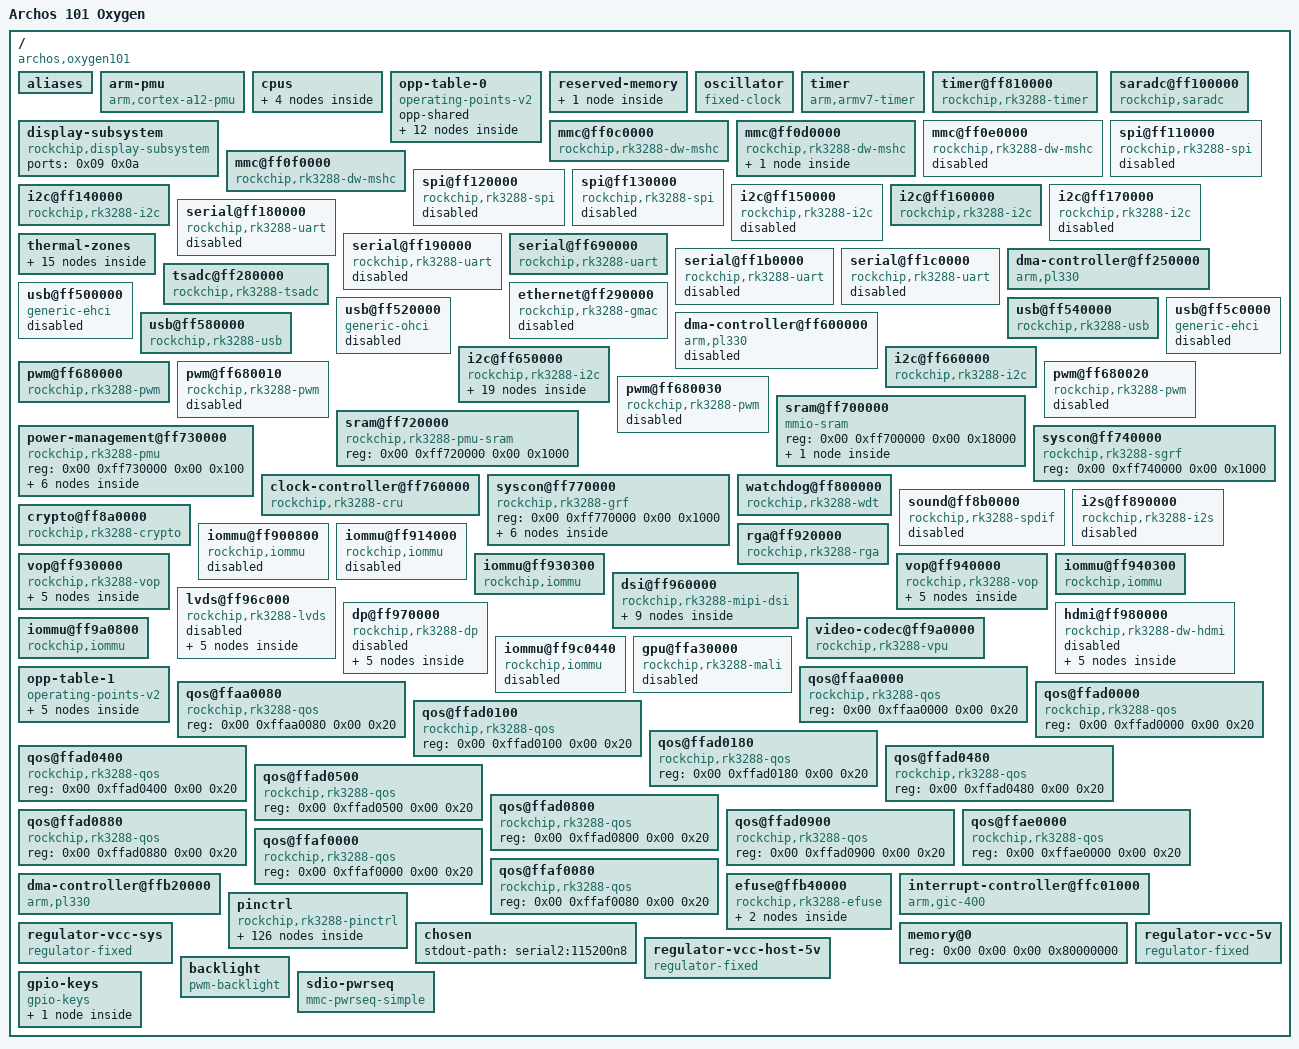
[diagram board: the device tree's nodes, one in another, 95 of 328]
/dts-v1/;

/ {
	#address-cells = <0x02>;
	#size-cells = <0x02>;
	compatible = "archos,oxygen101", "rockchip,rk3288";
	interrupt-parent = <0x01>;
	model = "Archos 101 Oxygen";

	aliases {
		ethernet0 = "/ethernet@ff290000";
		gpio0 = "/pinctrl/gpio@ff750000";
		gpio1 = "/pinctrl/gpio@ff780000";
		gpio2 = "/pinctrl/gpio@ff790000";
		gpio3 = "/pinctrl/gpio@ff7a0000";
		gpio4 = "/pinctrl/gpio@ff7b0000";
		gpio5 = "/pinctrl/gpio@ff7c0000";
		gpio6 = "/pinctrl/gpio@ff7d0000";
		gpio7 = "/pinctrl/gpio@ff7e0000";
		gpio8 = "/pinctrl/gpio@ff7f0000";
		i2c0 = "/i2c@ff650000";
		i2c1 = "/i2c@ff140000";
		i2c2 = "/i2c@ff660000";
		i2c3 = "/i2c@ff150000";
		i2c4 = "/i2c@ff160000";
		i2c5 = "/i2c@ff170000";
		mshc0 = "/mmc@ff0f0000";
		mshc1 = "/mmc@ff0c0000";
		mshc2 = "/mmc@ff0d0000";
		mshc3 = "/mmc@ff0e0000";
		serial0 = "/serial@ff180000";
		serial1 = "/serial@ff190000";
		serial2 = "/serial@ff690000";
		serial3 = "/serial@ff1b0000";
		serial4 = "/serial@ff1c0000";
		spi0 = "/spi@ff110000";
		spi1 = "/spi@ff120000";
		spi2 = "/spi@ff130000";
		mmc0 = "/mmc@ff0f0000";
		mmc1 = "/mmc@ff0c0000";
		mmc2 = "/mmc@ff0d0000";
	};

	arm-pmu {
		compatible = "arm,cortex-a12-pmu";
		interrupts = <0x00 0x97 0x04 0x00 0x98 0x04 0x00 0x99 0x04 0x00 0x9a 0x04>;
		interrupt-affinity = <0x02 0x03 0x04 0x05>;
	};

	cpus {
		#address-cells = <0x01>;
		#size-cells = <0x00>;
		enable-method = "rockchip,rk3066-smp";
		rockchip,pmu = <0x06>;

		cpu@500 {
			device_type = "cpu";
			compatible = "arm,cortex-a12";
			reg = <0x500>;
			resets = <0x07 0x00>;
			#cooling-cells = <0x02>;
			clock-latency = <0x9c40>;
			clocks = <0x07 0x06>;
			dynamic-power-coefficient = <0x172>;
			phandle = <0x02>;
		};

		cpu@501 {
			device_type = "cpu";
			compatible = "arm,cortex-a12";
			reg = <0x501>;
			resets = <0x07 0x01>;
			#cooling-cells = <0x02>;
			clock-latency = <0x9c40>;
			clocks = <0x07 0x06>;
			dynamic-power-coefficient = <0x172>;
			phandle = <0x03>;
		};

		cpu@502 {
			device_type = "cpu";
			compatible = "arm,cortex-a12";
			reg = <0x502>;
			resets = <0x07 0x02>;
			#cooling-cells = <0x02>;
			clock-latency = <0x9c40>;
			clocks = <0x07 0x06>;
			dynamic-power-coefficient = <0x172>;
			phandle = <0x04>;
		};

		cpu@503 {
			device_type = "cpu";
			compatible = "arm,cortex-a12";
			reg = <0x503>;
			resets = <0x07 0x03>;
			#cooling-cells = <0x02>;
			clock-latency = <0x9c40>;
			clocks = <0x07 0x06>;
			dynamic-power-coefficient = <0x172>;
			phandle = <0x05>;
		};
	};

	opp-table-0 {
		compatible = "operating-points-v2";
		opp-shared;

		opp-126000000 {
			opp-hz = <0x00 0x7829b80>;
			opp-microvolt = <0xdbba0>;
		};

		opp-216000000 {
			opp-hz = <0x00 0xcdfe600>;
			opp-microvolt = <0xdbba0>;
		};

		opp-312000000 {
			opp-hz = <0x00 0x1298be00>;
			opp-microvolt = <0xdbba0>;
		};

		opp-408000000 {
			opp-hz = <0x00 0x18519600>;
			opp-microvolt = <0xdbba0>;
		};

		opp-600000000 {
			opp-hz = <0x00 0x23c34600>;
			opp-microvolt = <0xdbba0>;
		};

		opp-696000000 {
			opp-hz = <0x00 0x297c1e00>;
			opp-microvolt = <0xe7ef0>;
		};

		opp-816000000 {
			opp-hz = <0x00 0x30a32c00>;
			opp-microvolt = <0xf4240>;
		};

		opp-1008000000 {
			opp-hz = <0x00 0x3c14dc00>;
			opp-microvolt = <0x100590>;
		};

		opp-1200000000 {
			opp-hz = <0x00 0x47868c00>;
			opp-microvolt = <0x10c8e0>;
		};

		opp-1416000000 {
			opp-hz = <0x00 0x54667200>;
			opp-microvolt = <0x124f80>;
		};

		opp-1512000000 {
			opp-hz = <0x00 0x5a1f4a00>;
			opp-microvolt = <0x13d620>;
		};

		opp-1608000000 {
			opp-hz = <0x00 0x5fd82200>;
			opp-microvolt = <0x149970>;
		};
	};

	reserved-memory {
		#address-cells = <0x02>;
		#size-cells = <0x02>;
		ranges;

		dma-unusable@fe000000 {
			reg = <0x00 0xfe000000 0x00 0x1000000>;
		};
	};

	oscillator {
		compatible = "fixed-clock";
		clock-frequency = <0x16e3600>;
		clock-output-names = "xin24m";
		#clock-cells = <0x00>;
		phandle = <0x08>;
	};

	timer {
		compatible = "arm,armv7-timer";
		arm,cpu-registers-not-fw-configured;
		interrupts = <0x01 0x0d 0xf04 0x01 0x0e 0xf04 0x01 0x0b 0xf04 0x01 0x0a 0xf04>;
		clock-frequency = <0x16e3600>;
		arm,no-tick-in-suspend;
	};

	timer@ff810000 {
		compatible = "rockchip,rk3288-timer";
		reg = <0x00 0xff810000 0x00 0x20>;
		interrupts = <0x00 0x48 0x04>;
		clocks = <0x07 0x161 0x08>;
		clock-names = "pclk", "timer";
	};

	display-subsystem {
		compatible = "rockchip,display-subsystem";
		ports = <0x09 0x0a>;
	};

	mmc@ff0c0000 {
		compatible = "rockchip,rk3288-dw-mshc";
		max-frequency = <0x8f0d180>;
		clocks = <0x07 0x1c8 0x07 0x44 0x07 0x72 0x07 0x76>;
		clock-names = "biu", "ciu", "ciu-drive", "ciu-sample";
		fifo-depth = <0x100>;
		interrupts = <0x00 0x20 0x04>;
		reg = <0x00 0xff0c0000 0x00 0x4000>;
		resets = <0x07 0x80>;
		reset-names = "reset";
		status = "okay";
		bus-width = <0x04>;
		cap-sd-highspeed;
		broken-cd;
		card-detect-delay = <0xc8>;
		disable-wp;
		pinctrl-names = "default";
		pinctrl-0 = <0x0b 0x0c 0x0d>;
		vmmc-supply = <0x0e>;
	};

	mmc@ff0d0000 {
		compatible = "rockchip,rk3288-dw-mshc";
		max-frequency = <0x8f0d180>;
		clocks = <0x07 0x1c9 0x07 0x45 0x07 0x73 0x07 0x77>;
		clock-names = "biu", "ciu", "ciu-drive", "ciu-sample";
		fifo-depth = <0x100>;
		interrupts = <0x00 0x21 0x04>;
		reg = <0x00 0xff0d0000 0x00 0x4000>;
		resets = <0x07 0x81>;
		reset-names = "reset";
		status = "okay";
		#address-cells = <0x01>;
		#size-cells = <0x00>;
		bus-width = <0x04>;
		cap-sd-highspeed;
		cap-sdio-irq;
		keep-power-in-suspend;
		mmc-pwrseq = <0x0f>;
		non-removable;
		pinctrl-names = "default";
		pinctrl-0 = <0x10 0x11 0x12>;
		vmmc-supply = <0x13>;
		vqmmc-supply = <0x14>;

		wifi@1 {
			compatible = "brcm,bcm4329-fmac";
			reg = <0x01>;
			interrupt-parent = <0x15>;
			interrupts = <0x1e 0x04>;
			interrupt-names = "host-wake";
		};
	};

	mmc@ff0e0000 {
		compatible = "rockchip,rk3288-dw-mshc";
		max-frequency = <0x8f0d180>;
		clocks = <0x07 0x1ca 0x07 0x46 0x07 0x74 0x07 0x78>;
		clock-names = "biu", "ciu", "ciu-drive", "ciu-sample";
		fifo-depth = <0x100>;
		interrupts = <0x00 0x22 0x04>;
		reg = <0x00 0xff0e0000 0x00 0x4000>;
		resets = <0x07 0x82>;
		reset-names = "reset";
		status = "disabled";
	};

	mmc@ff0f0000 {
		compatible = "rockchip,rk3288-dw-mshc";
		max-frequency = <0x8f0d180>;
		clocks = <0x07 0x1cb 0x07 0x47 0x07 0x75 0x07 0x79>;
		clock-names = "biu", "ciu", "ciu-drive", "ciu-sample";
		fifo-depth = <0x100>;
		interrupts = <0x00 0x23 0x04>;
		reg = <0x00 0xff0f0000 0x00 0x4000>;
		resets = <0x07 0x83>;
		reset-names = "reset";
		status = "okay";
		bus-width = <0x08>;
		cap-mmc-highspeed;
		non-removable;
		pinctrl-names = "default";
		pinctrl-0 = <0x16 0x17 0x18 0x19>;
		vmmc-supply = <0x13>;
		vqmmc-supply = <0x1a>;
	};

	saradc@ff100000 {
		compatible = "rockchip,saradc";
		reg = <0x00 0xff100000 0x00 0x100>;
		interrupts = <0x00 0x24 0x04>;
		#io-channel-cells = <0x01>;
		clocks = <0x07 0x49 0x07 0x15b>;
		clock-names = "saradc", "apb_pclk";
		resets = <0x07 0x57>;
		reset-names = "saradc-apb";
		status = "okay";
		vref-supply = <0x1a>;
	};

	spi@ff110000 {
		compatible = "rockchip,rk3288-spi", "rockchip,rk3066-spi";
		clocks = <0x07 0x41 0x07 0x152>;
		clock-names = "spiclk", "apb_pclk";
		dmas = <0x1b 0x0b 0x1b 0x0c>;
		dma-names = "tx", "rx";
		interrupts = <0x00 0x2c 0x04>;
		pinctrl-names = "default";
		pinctrl-0 = <0x1c 0x1d 0x1e 0x1f>;
		reg = <0x00 0xff110000 0x00 0x1000>;
		#address-cells = <0x01>;
		#size-cells = <0x00>;
		status = "disabled";
	};

	spi@ff120000 {
		compatible = "rockchip,rk3288-spi", "rockchip,rk3066-spi";
		clocks = <0x07 0x42 0x07 0x153>;
		clock-names = "spiclk", "apb_pclk";
		dmas = <0x1b 0x0d 0x1b 0x0e>;
		dma-names = "tx", "rx";
		interrupts = <0x00 0x2d 0x04>;
		pinctrl-names = "default";
		pinctrl-0 = <0x20 0x21 0x22 0x23>;
		reg = <0x00 0xff120000 0x00 0x1000>;
		#address-cells = <0x01>;
		#size-cells = <0x00>;
		status = "disabled";
	};

	spi@ff130000 {
		compatible = "rockchip,rk3288-spi", "rockchip,rk3066-spi";
		clocks = <0x07 0x43 0x07 0x154>;
		clock-names = "spiclk", "apb_pclk";
		dmas = <0x1b 0x0f 0x1b 0x10>;
		dma-names = "tx", "rx";
		interrupts = <0x00 0x2e 0x04>;
		pinctrl-names = "default";
		pinctrl-0 = <0x24 0x25 0x26 0x27>;
		reg = <0x00 0xff130000 0x00 0x1000>;
		#address-cells = <0x01>;
		#size-cells = <0x00>;
		status = "disabled";
	};

	i2c@ff140000 {
		compatible = "rockchip,rk3288-i2c";
		reg = <0x00 0xff140000 0x00 0x1000>;
		interrupts = <0x00 0x3e 0x04>;
		#address-cells = <0x01>;
		#size-cells = <0x00>;
		clock-names = "i2c";
		clocks = <0x07 0x14d>;
		pinctrl-names = "default";
		pinctrl-0 = <0x28>;
		status = "okay";
	};

	i2c@ff150000 {
		compatible = "rockchip,rk3288-i2c";
		reg = <0x00 0xff150000 0x00 0x1000>;
		interrupts = <0x00 0x3f 0x04>;
		#address-cells = <0x01>;
		#size-cells = <0x00>;
		clock-names = "i2c";
		clocks = <0x07 0x14f>;
		pinctrl-names = "default";
		pinctrl-0 = <0x29>;
		status = "disabled";
	};

	i2c@ff160000 {
		compatible = "rockchip,rk3288-i2c";
		reg = <0x00 0xff160000 0x00 0x1000>;
		interrupts = <0x00 0x40 0x04>;
		#address-cells = <0x01>;
		#size-cells = <0x00>;
		clock-names = "i2c";
		clocks = <0x07 0x150>;
		pinctrl-names = "default";
		pinctrl-0 = <0x2a>;
		status = "okay";
	};

	i2c@ff170000 {
		compatible = "rockchip,rk3288-i2c";
		reg = <0x00 0xff170000 0x00 0x1000>;
		interrupts = <0x00 0x41 0x04>;
		#address-cells = <0x01>;
		#size-cells = <0x00>;
		clock-names = "i2c";
		clocks = <0x07 0x151>;
		pinctrl-names = "default";
		pinctrl-0 = <0x2b>;
		status = "disabled";
	};

	serial@ff180000 {
		compatible = "rockchip,rk3288-uart", "snps,dw-apb-uart";
		reg = <0x00 0xff180000 0x00 0x100>;
		interrupts = <0x00 0x37 0x04>;
		reg-shift = <0x02>;
		reg-io-width = <0x04>;
		clocks = <0x07 0x4d 0x07 0x155>;
		clock-names = "baudclk", "apb_pclk";
		dmas = <0x1b 0x01 0x1b 0x02>;
		dma-names = "tx", "rx";
		pinctrl-names = "default";
		pinctrl-0 = <0x2c>;
		status = "disabled";
	};

	serial@ff190000 {
		compatible = "rockchip,rk3288-uart", "snps,dw-apb-uart";
		reg = <0x00 0xff190000 0x00 0x100>;
		interrupts = <0x00 0x38 0x04>;
		reg-shift = <0x02>;
		reg-io-width = <0x04>;
		clocks = <0x07 0x4e 0x07 0x156>;
		clock-names = "baudclk", "apb_pclk";
		dmas = <0x1b 0x03 0x1b 0x04>;
		dma-names = "tx", "rx";
		pinctrl-names = "default";
		pinctrl-0 = <0x2d>;
		status = "disabled";
	};

	serial@ff690000 {
		compatible = "rockchip,rk3288-uart", "snps,dw-apb-uart";
		reg = <0x00 0xff690000 0x00 0x100>;
		interrupts = <0x00 0x39 0x04>;
		reg-shift = <0x02>;
		reg-io-width = <0x04>;
		clocks = <0x07 0x4f 0x07 0x157>;
		clock-names = "baudclk", "apb_pclk";
		pinctrl-names = "default";
		pinctrl-0 = <0x2e>;
		status = "okay";
	};

	serial@ff1b0000 {
		compatible = "rockchip,rk3288-uart", "snps,dw-apb-uart";
		reg = <0x00 0xff1b0000 0x00 0x100>;
		interrupts = <0x00 0x3a 0x04>;
		reg-shift = <0x02>;
		reg-io-width = <0x04>;
		clocks = <0x07 0x50 0x07 0x158>;
		clock-names = "baudclk", "apb_pclk";
		dmas = <0x1b 0x07 0x1b 0x08>;
		dma-names = "tx", "rx";
		pinctrl-names = "default";
		pinctrl-0 = <0x2f>;
		status = "disabled";
	};

	serial@ff1c0000 {
		compatible = "rockchip,rk3288-uart", "snps,dw-apb-uart";
		reg = <0x00 0xff1c0000 0x00 0x100>;
		interrupts = <0x00 0x3b 0x04>;
		reg-shift = <0x02>;
		reg-io-width = <0x04>;
		clocks = <0x07 0x51 0x07 0x159>;
		clock-names = "baudclk", "apb_pclk";
		dmas = <0x1b 0x09 0x1b 0x0a>;
		dma-names = "tx", "rx";
		pinctrl-names = "default";
		pinctrl-0 = <0x30>;
		status = "disabled";
	};

	dma-controller@ff250000 {
		compatible = "arm,pl330", "arm,primecell";
		reg = <0x00 0xff250000 0x00 0x4000>;
		interrupts = <0x00 0x02 0x04 0x00 0x03 0x04>;
		#dma-cells = <0x01>;
		arm,pl330-broken-no-flushp;
		arm,pl330-periph-burst;
		clocks = <0x07 0xc2>;
		clock-names = "apb_pclk";
		phandle = <0x1b>;
	};

	thermal-zones {

		reserve-thermal {
			polling-delay-passive = <0x3e8>;
			polling-delay = <0x1388>;
			thermal-sensors = <0x31 0x00>;
		};

		cpu-thermal {
			polling-delay-passive = <0x64>;
			polling-delay = <0x1388>;
			thermal-sensors = <0x31 0x01>;

			trips {

				cpu_alert0 {
					temperature = <0x11170>;
					hysteresis = <0x7d0>;
					type = "passive";
					phandle = <0x32>;
				};

				cpu_alert1 {
					temperature = <0x124f8>;
					hysteresis = <0x7d0>;
					type = "passive";
					phandle = <0x33>;
				};

				cpu_crit {
					temperature = <0x15f90>;
					hysteresis = <0x7d0>;
					type = "critical";
				};
			};

			cooling-maps {

				map0 {
					trip = <0x32>;
					cooling-device = <0x02 0xffffffff 0x06 0x03 0xffffffff 0x06 0x04 0xffffffff 0x06 0x05 0xffffffff 0x06>;
				};

				map1 {
					trip = <0x33>;
					cooling-device = <0x02 0xffffffff 0xffffffff 0x03 0xffffffff 0xffffffff 0x04 0xffffffff 0xffffffff 0x05 0xffffffff 0xffffffff>;
				};
			};
		};

		gpu-thermal {
			polling-delay-passive = <0x64>;
			polling-delay = <0x1388>;
			thermal-sensors = <0x31 0x02>;

			trips {

				gpu_alert0 {
					temperature = <0x11170>;
					hysteresis = <0x7d0>;
					type = "passive";
					phandle = <0x34>;
				};

				gpu_crit {
					temperature = <0x15f90>;
					hysteresis = <0x7d0>;
					type = "critical";
				};
			};

			cooling-maps {

				map0 {
					trip = <0x34>;
					cooling-device = <0x35 0xffffffff 0xffffffff>;
				};
			};
		};
	};

	tsadc@ff280000 {
		compatible = "rockchip,rk3288-tsadc";
		reg = <0x00 0xff280000 0x00 0x100>;
		interrupts = <0x00 0x25 0x04>;
		clocks = <0x07 0x48 0x07 0x15a>;
		clock-names = "tsadc", "apb_pclk";
		resets = <0x07 0x9f>;
		reset-names = "tsadc-apb";
		pinctrl-names = "init", "default", "sleep";
		pinctrl-0 = <0x36>;
		pinctrl-1 = <0x37>;
		pinctrl-2 = <0x36>;
		#thermal-sensor-cells = <0x01>;
		rockchip,grf = <0x38>;
		rockchip,hw-tshut-temp = <0x17318>;
		status = "okay";
		phandle = <0x31>;
	};

	ethernet@ff290000 {
		compatible = "rockchip,rk3288-gmac";
		reg = <0x00 0xff290000 0x00 0x10000>;
		interrupts = <0x00 0x1b 0x04 0x00 0x1c 0x04>;
		interrupt-names = "macirq", "eth_wake_irq";
		rockchip,grf = <0x38>;
		clocks = <0x07 0x97 0x07 0x66 0x07 0x67 0x07 0x63 0x07 0x98 0x07 0xc4 0x07 0x15d>;
		clock-names = "stmmaceth", "mac_clk_rx", "mac_clk_tx", "clk_mac_ref", "clk_mac_refout", "aclk_mac", "pclk_mac";
		resets = <0x07 0x42>;
		reset-names = "stmmaceth";
		status = "disabled";
	};

	usb@ff500000 {
		compatible = "generic-ehci";
		reg = <0x00 0xff500000 0x00 0x100>;
		interrupts = <0x00 0x18 0x04>;
		clocks = <0x07 0x1c2>;
		phys = <0x39>;
		phy-names = "usb";
		status = "disabled";
	};

	usb@ff520000 {
		compatible = "generic-ohci";
		reg = <0x00 0xff520000 0x00 0x100>;
		interrupts = <0x00 0x29 0x04>;
		clocks = <0x07 0x1c2>;
		phys = <0x39>;
		phy-names = "usb";
		status = "disabled";
	};

	usb@ff540000 {
		compatible = "rockchip,rk3288-usb", "rockchip,rk3066-usb", "snps,dwc2";
		reg = <0x00 0xff540000 0x00 0x40000>;
		interrupts = <0x00 0x19 0x04>;
		clocks = <0x07 0x1c3>;
		clock-names = "otg";
		dr_mode = "host";
		phys = <0x3a>;
		phy-names = "usb2-phy";
		snps,reset-phy-on-wake;
		status = "okay";
		vbus-supply = <0x3b>;
	};

	usb@ff580000 {
		compatible = "rockchip,rk3288-usb", "rockchip,rk3066-usb", "snps,dwc2";
		reg = <0x00 0xff580000 0x00 0x40000>;
		interrupts = <0x00 0x17 0x04>;
		clocks = <0x07 0x1c1>;
		clock-names = "otg";
		dr_mode = "peripheral";
		g-np-tx-fifo-size = <0x10>;
		g-rx-fifo-size = <0x113>;
		g-tx-fifo-size = <0x100 0x80 0x80 0x40 0x40 0x20>;
		phys = <0x3c>;
		phy-names = "usb2-phy";
		status = "okay";
	};

	usb@ff5c0000 {
		compatible = "generic-ehci";
		reg = <0x00 0xff5c0000 0x00 0x100>;
		interrupts = <0x00 0x1a 0x04>;
		clocks = <0x07 0x1c4>;
		status = "disabled";
	};

	dma-controller@ff600000 {
		compatible = "arm,pl330", "arm,primecell";
		reg = <0x00 0xff600000 0x00 0x4000>;
		interrupts = <0x00 0x00 0x04 0x00 0x01 0x04>;
		#dma-cells = <0x01>;
		arm,pl330-broken-no-flushp;
		arm,pl330-periph-burst;
		clocks = <0x07 0xc1>;
		clock-names = "apb_pclk";
		status = "disabled";
	};

	i2c@ff650000 {
		compatible = "rockchip,rk3288-i2c";
		reg = <0x00 0xff650000 0x00 0x1000>;
		interrupts = <0x00 0x3c 0x04>;
		#address-cells = <0x01>;
		#size-cells = <0x00>;
		clock-names = "i2c";
		clocks = <0x07 0x14c>;
		pinctrl-names = "default";
		pinctrl-0 = <0x3d>;
		status = "okay";
		clock-frequency = <0x61a80>;

		pmic@32 {
			compatible = "ricoh,rc5t619";
			reg = <0x32>;
			interrupt-parent = <0x3e>;
			interrupts = <0x04 0x08>;
			system-power-controller;

			regulators {

				DCDC1 {
					regulator-name = "vccio";
					regulator-min-microvolt = <0x325aa0>;
					regulator-max-microvolt = <0x325aa0>;
					regulator-always-on;
					regulator-boot-on;
					phandle = <0x13>;
				};

				DCDC2 {
					regulator-name = "ricoh_dcdc2";
					regulator-min-microvolt = <0x1e8480>;
					regulator-max-microvolt = <0x1e8480>;
					regulator-always-on;
					regulator-boot-on;
				};

				DCDC3 {
					regulator-name = "vcc_lcd";
					regulator-min-microvolt = <0x325aa0>;
					regulator-max-microvolt = <0x325aa0>;
					regulator-always-on;
					regulator-boot-on;
					phandle = <0x64>;
				};

				DCDC4 {
					regulator-name = "vdd_logic";
					regulator-min-microvolt = <0xaae60>;
					regulator-max-microvolt = <0x16e360>;
					regulator-always-on;
					regulator-boot-on;
				};

				DCDC5 {
					regulator-name = "vcc_ddr";
					regulator-min-microvolt = <0x124f80>;
					regulator-max-microvolt = <0x124f80>;
					regulator-always-on;
					regulator-boot-on;
				};

				LDO1 {
					regulator-name = "vccio_pmu";
					regulator-min-microvolt = <0x325aa0>;
					regulator-max-microvolt = <0x325aa0>;
					regulator-always-on;
					regulator-boot-on;
				};

				LDO2 {
					regulator-name = "ricoh_ldo2";
					regulator-min-microvolt = <0x325aa0>;
					regulator-max-microvolt = <0x325aa0>;
					regulator-always-on;
					regulator-boot-on;
				};

				LDO3 {
					regulator-name = "ricoh_ldo3";
					regulator-min-microvolt = <0x325aa0>;
					regulator-max-microvolt = <0x325aa0>;
					regulator-always-on;
					regulator-boot-on;
				};

				LDO4 {
					regulator-name = "vcc_sd";
					regulator-min-microvolt = <0x325aa0>;
					regulator-max-microvolt = <0x325aa0>;
					regulator-always-on;
					regulator-boot-on;
					phandle = <0x0e>;
				};

				LDO5 {
					regulator-name = "vcc_wl";
					regulator-min-microvolt = <0x1b7740>;
					regulator-max-microvolt = <0x1b7740>;
					regulator-always-on;
					regulator-boot-on;
					phandle = <0x14>;
				};

				LDO6 {
					regulator-name = "ricoh_ldo6";
					regulator-min-microvolt = <0x1b7740>;
					regulator-max-microvolt = <0x1b7740>;
					regulator-always-on;
					regulator-boot-on;
				};

				LDO7 {
					regulator-name = "ricoh_ldo7";
					regulator-min-microvolt = <0xf4240>;
					regulator-max-microvolt = <0xf4240>;
					regulator-always-on;
					regulator-boot-on;
				};

				LDO8 {
					regulator-name = "ricoh_ldo8";
					regulator-min-microvolt = <0x325aa0>;
					regulator-max-microvolt = <0x325aa0>;
					regulator-always-on;
					regulator-boot-on;
				};

				LDO9 {
					regulator-name = "ricoh_ldo9";
					regulator-min-microvolt = <0xf4240>;
					regulator-max-microvolt = <0xf4240>;
					regulator-always-on;
					regulator-boot-on;
				};

				LDO10 {
					regulator-name = "vcc_18";
					regulator-min-microvolt = <0x1b7740>;
					regulator-max-microvolt = <0x1b7740>;
					regulator-always-on;
					regulator-boot-on;
					phandle = <0x1a>;
				};

				LDORTC1 {
					regulator-name = "ricoh_ldortc1";
					regulator-min-microvolt = <0x325aa0>;
					regulator-max-microvolt = <0x325aa0>;
					regulator-always-on;
					regulator-boot-on;
				};

				LDORTC2 {
					regulator-name = "ricoh_ldortc2";
					regulator-min-microvolt = <0x325aa0>;
					regulator-max-microvolt = <0x325aa0>;
					regulator-always-on;
					regulator-boot-on;
				};
			};
		};
	};

	i2c@ff660000 {
		compatible = "rockchip,rk3288-i2c";
		reg = <0x00 0xff660000 0x00 0x1000>;
		interrupts = <0x00 0x3d 0x04>;
		#address-cells = <0x01>;
		#size-cells = <0x00>;
		clock-names = "i2c";
		clocks = <0x07 0x14e>;
		pinctrl-names = "default";
		pinctrl-0 = <0x3f>;
		status = "okay";
	};

	pwm@ff680000 {
		compatible = "rockchip,rk3288-pwm";
		reg = <0x00 0xff680000 0x00 0x10>;
		#pwm-cells = <0x03>;
		pinctrl-names = "default";
		pinctrl-0 = <0x40>;
		clocks = <0x07 0x15f>;
		status = "okay";
		phandle = <0x78>;
	};

	pwm@ff680010 {
		compatible = "rockchip,rk3288-pwm";
		reg = <0x00 0xff680010 0x00 0x10>;
		#pwm-cells = <0x03>;
		pinctrl-names = "default";
		pinctrl-0 = <0x41>;
		clocks = <0x07 0x15f>;
		status = "disabled";
	};

	pwm@ff680020 {
		compatible = "rockchip,rk3288-pwm";
		reg = <0x00 0xff680020 0x00 0x10>;
		#pwm-cells = <0x03>;
		pinctrl-names = "default";
		pinctrl-0 = <0x42>;
		clocks = <0x07 0x15f>;
		status = "disabled";
	};

	pwm@ff680030 {
		compatible = "rockchip,rk3288-pwm";
		reg = <0x00 0xff680030 0x00 0x10>;
		#pwm-cells = <0x03>;
		pinctrl-names = "default";
		pinctrl-0 = <0x43>;
		clocks = <0x07 0x15f>;
		status = "disabled";
	};

	sram@ff700000 {
		compatible = "mmio-sram";
		reg = <0x00 0xff700000 0x00 0x18000>;
		#address-cells = <0x01>;
		#size-cells = <0x01>;
		ranges = <0x00 0x00 0xff700000 0x18000>;

		smp-sram@0 {
			compatible = "rockchip,rk3066-smp-sram";
			reg = <0x00 0x10>;
		};
	};

	sram@ff720000 {
		compatible = "rockchip,rk3288-pmu-sram", "mmio-sram";
		reg = <0x00 0xff720000 0x00 0x1000>;
	};

	power-management@ff730000 {
		compatible = "rockchip,rk3288-pmu", "syscon", "simple-mfd";
		reg = <0x00 0xff730000 0x00 0x100>;
		phandle = <0x06>;

		power-controller {
			compatible = "rockchip,rk3288-power-controller";
			#power-domain-cells = <0x01>;
			#address-cells = <0x01>;
			#size-cells = <0x00>;
			assigned-clocks = <0x07 0x68>;
			assigned-clock-parents = <0x08>;
			phandle = <0x55>;

			power-domain@9 {
				reg = <0x09>;
				clocks = <0x07 0xca 0x07 0xcd 0x07 0xc8 0x07 0xcc 0x07 0xc5 0x07 0xc6 0x07 0xbe 0x07 0xbf 0x07 0x1d4 0x07 0x1d5 0x07 0x1d6 0x07 0x1d9 0x07 0x1d1 0x07 0x1d2 0x07 0x163 0x07 0x168 0x07 0x167 0x07 0x166 0x07 0x164 0x07 0x165 0x07 0x68 0x07 0x69 0x07 0x6c 0x07 0x6b 0x07 0x6a>;
				pm_qos = <0x44 0x45 0x46 0x47 0x48 0x49 0x4a 0x4b 0x4c>;
				#power-domain-cells = <0x00>;
			};

			power-domain@11 {
				reg = <0x0b>;
				clocks = <0x07 0xcf 0x07 0x6f 0x07 0x70>;
				pm_qos = <0x4d 0x4e>;
				#power-domain-cells = <0x00>;
			};

			power-domain@12 {
				reg = <0x0c>;
				clocks = <0x07 0xd0 0x07 0x1dc>;
				pm_qos = <0x4f>;
				#power-domain-cells = <0x00>;
			};

			power-domain@13 {
				reg = <0x0d>;
				clocks = <0x07 0xc0>;
				pm_qos = <0x50 0x51>;
				#power-domain-cells = <0x00>;
			};
		};

		reboot-mode {
			compatible = "syscon-reboot-mode";
			offset = <0x94>;
			mode-normal = <0x5242c300>;
			mode-recovery = <0x5242c303>;
			mode-bootloader = <0x5242c309>;
			mode-loader = <0x5242c301>;
		};
	};

	syscon@ff740000 {
		compatible = "rockchip,rk3288-sgrf", "syscon";
		reg = <0x00 0xff740000 0x00 0x1000>;
	};

	clock-controller@ff760000 {
		compatible = "rockchip,rk3288-cru";
		reg = <0x00 0xff760000 0x00 0x1000>;
		clocks = <0x08>;
		clock-names = "xin24m";
		rockchip,grf = <0x38>;
		#clock-cells = <0x01>;
		#reset-cells = <0x01>;
		assigned-clocks = <0x07 0xbe 0x07 0xbf 0x07 0x04 0x07 0x03 0x07 0x05 0x07 0xd1 0x07 0x1dd 0x07 0x16a 0x07 0xd2 0x07 0x1de 0x07 0x16b>;
		assigned-clock-rates = <0x00 0x00 0x2367b880 0x17d78400 0x1dcd6500 0x11e1a300 0x8f0d180 0x47868c0 0x11e1a300 0x8f0d180 0x47868c0>;
		phandle = <0x07>;
	};

	syscon@ff770000 {
		compatible = "rockchip,rk3288-grf", "syscon", "simple-mfd";
		reg = <0x00 0xff770000 0x00 0x1000>;
		phandle = <0x38>;

		edp-phy {
			compatible = "rockchip,rk3288-dp-phy";
			clocks = <0x07 0x68>;
			clock-names = "24m";
			#phy-cells = <0x00>;
			status = "disabled";
			phandle = <0x69>;
		};

		io-domains {
			compatible = "rockchip,rk3288-io-voltage-domain";
			status = "disabled";
		};

		usbphy {
			compatible = "rockchip,rk3288-usb-phy";
			#address-cells = <0x01>;
			#size-cells = <0x00>;
			status = "okay";

			usb-phy@320 {
				#phy-cells = <0x00>;
				reg = <0x320>;
				clocks = <0x07 0x5d>;
				clock-names = "phyclk";
				#clock-cells = <0x00>;
				resets = <0x07 0x85>;
				reset-names = "phy-reset";
				phandle = <0x3c>;
			};

			usb-phy@334 {
				#phy-cells = <0x00>;
				reg = <0x334>;
				clocks = <0x07 0x5e>;
				clock-names = "phyclk";
				#clock-cells = <0x00>;
				resets = <0x07 0x88>;
				reset-names = "phy-reset";
				phandle = <0x39>;
			};

			usb-phy@348 {
				#phy-cells = <0x00>;
				reg = <0x348>;
				clocks = <0x07 0x5f>;
				clock-names = "phyclk";
				#clock-cells = <0x00>;
				resets = <0x07 0x8b>;
				reset-names = "phy-reset";
				phandle = <0x3a>;
			};
		};
	};

	watchdog@ff800000 {
		compatible = "rockchip,rk3288-wdt", "snps,dw-wdt";
		reg = <0x00 0xff800000 0x00 0x100>;
		clocks = <0x07 0x170>;
		interrupts = <0x00 0x4f 0x04>;
		status = "okay";
	};

	sound@ff8b0000 {
		compatible = "rockchip,rk3288-spdif", "rockchip,rk3066-spdif";
		reg = <0x00 0xff8b0000 0x00 0x10000>;
		#sound-dai-cells = <0x00>;
		clocks = <0x07 0x54 0x07 0x1d0>;
		clock-names = "mclk", "hclk";
		dmas = <0x52 0x03>;
		dma-names = "tx";
		interrupts = <0x00 0x36 0x04>;
		pinctrl-names = "default";
		pinctrl-0 = <0x53>;
		rockchip,grf = <0x38>;
		status = "disabled";
	};

	i2s@ff890000 {
		compatible = "rockchip,rk3288-i2s", "rockchip,rk3066-i2s";
		reg = <0x00 0xff890000 0x00 0x10000>;
		#sound-dai-cells = <0x00>;
		interrupts = <0x00 0x35 0x04>;
		clocks = <0x07 0x52 0x07 0x1ce>;
		clock-names = "i2s_clk", "i2s_hclk";
		dmas = <0x52 0x00 0x52 0x01>;
		dma-names = "tx", "rx";
		pinctrl-names = "default";
		pinctrl-0 = <0x54>;
		rockchip,playback-channels = <0x08>;
		rockchip,capture-channels = <0x02>;
		status = "disabled";
	};

	crypto@ff8a0000 {
		compatible = "rockchip,rk3288-crypto";
		reg = <0x00 0xff8a0000 0x00 0x4000>;
		interrupts = <0x00 0x30 0x04>;
		clocks = <0x07 0xc7 0x07 0x1cd 0x07 0x7d 0x07 0xc1>;
		clock-names = "aclk", "hclk", "sclk", "apb_pclk";
		resets = <0x07 0xae>;
		reset-names = "crypto-rst";
	};

	iommu@ff900800 {
		compatible = "rockchip,iommu";
		reg = <0x00 0xff900800 0x00 0x40>;
		interrupts = <0x00 0x11 0x04>;
		clocks = <0x07 0xca 0x07 0x1d4>;
		clock-names = "aclk", "iface";
		#iommu-cells = <0x00>;
		status = "disabled";
	};

	iommu@ff914000 {
		compatible = "rockchip,iommu";
		reg = <0x00 0xff914000 0x00 0x100 0x00 0xff915000 0x00 0x100>;
		interrupts = <0x00 0x0e 0x04>;
		clocks = <0x07 0xcd 0x07 0x1d5>;
		clock-names = "aclk", "iface";
		#iommu-cells = <0x00>;
		rockchip,disable-mmu-reset;
		status = "disabled";
	};

	rga@ff920000 {
		compatible = "rockchip,rk3288-rga";
		reg = <0x00 0xff920000 0x00 0x180>;
		interrupts = <0x00 0x12 0x04>;
		clocks = <0x07 0xc8 0x07 0x1d6 0x07 0x6a>;
		clock-names = "aclk", "hclk", "sclk";
		power-domains = <0x55 0x09>;
		resets = <0x07 0x69 0x07 0x6c 0x07 0x6d>;
		reset-names = "core", "axi", "ahb";
	};

	vop@ff930000 {
		compatible = "rockchip,rk3288-vop";
		reg = <0x00 0xff930000 0x00 0x19c 0x00 0xff931000 0x00 0x1000>;
		interrupts = <0x00 0x0f 0x04>;
		clocks = <0x07 0xc5 0x07 0xbe 0x07 0x1d1>;
		clock-names = "aclk_vop", "dclk_vop", "hclk_vop";
		power-domains = <0x55 0x09>;
		resets = <0x07 0x64 0x07 0x65 0x07 0x66>;
		reset-names = "axi", "ahb", "dclk";
		iommus = <0x56>;
		status = "okay";

		port {
			#address-cells = <0x01>;
			#size-cells = <0x00>;
			phandle = <0x0a>;

			endpoint@0 {
				reg = <0x00>;
				remote-endpoint = <0x57>;
				phandle = <0x6c>;
			};

			endpoint@1 {
				reg = <0x01>;
				remote-endpoint = <0x58>;
				phandle = <0x6a>;
			};

			endpoint@2 {
				reg = <0x02>;
				remote-endpoint = <0x59>;
				phandle = <0x60>;
			};

			endpoint@3 {
				reg = <0x03>;
				remote-endpoint = <0x5a>;
				phandle = <0x67>;
			};
		};
	};

	iommu@ff930300 {
		compatible = "rockchip,iommu";
		reg = <0x00 0xff930300 0x00 0x100>;
		interrupts = <0x00 0x0f 0x04>;
		clocks = <0x07 0xc5 0x07 0x1d1>;
		clock-names = "aclk", "iface";
		power-domains = <0x55 0x09>;
		#iommu-cells = <0x00>;
		status = "okay";
		phandle = <0x56>;
	};

	vop@ff940000 {
		compatible = "rockchip,rk3288-vop";
		reg = <0x00 0xff940000 0x00 0x19c 0x00 0xff941000 0x00 0x1000>;
		interrupts = <0x00 0x10 0x04>;
		clocks = <0x07 0xc6 0x07 0xbf 0x07 0x1d2>;
		clock-names = "aclk_vop", "dclk_vop", "hclk_vop";
		power-domains = <0x55 0x09>;
		resets = <0x07 0xb0 0x07 0xb1 0x07 0xb2>;
		reset-names = "axi", "ahb", "dclk";
		iommus = <0x5b>;
		status = "okay";

		port {
			#address-cells = <0x01>;
			#size-cells = <0x00>;
			phandle = <0x09>;

			endpoint@0 {
				reg = <0x00>;
				remote-endpoint = <0x5c>;
				phandle = <0x6d>;
			};

			endpoint@1 {
				reg = <0x01>;
				remote-endpoint = <0x5d>;
				phandle = <0x6b>;
			};

			endpoint@2 {
				reg = <0x02>;
				remote-endpoint = <0x5e>;
				phandle = <0x61>;
			};

			endpoint@3 {
				reg = <0x03>;
				remote-endpoint = <0x5f>;
				phandle = <0x68>;
			};
		};
	};

	iommu@ff940300 {
		compatible = "rockchip,iommu";
		reg = <0x00 0xff940300 0x00 0x100>;
		interrupts = <0x00 0x10 0x04>;
		clocks = <0x07 0xc6 0x07 0x1d2>;
		clock-names = "aclk", "iface";
		power-domains = <0x55 0x09>;
		#iommu-cells = <0x00>;
		status = "okay";
		phandle = <0x5b>;
	};

	dsi@ff960000 {
		compatible = "rockchip,rk3288-mipi-dsi", "snps,dw-mipi-dsi";
		reg = <0x00 0xff960000 0x00 0x4000>;
		interrupts = <0x00 0x13 0x04>;
		clocks = <0x07 0x7e 0x07 0x164>;
		clock-names = "ref", "pclk";
		power-domains = <0x55 0x09>;
		rockchip,grf = <0x38>;
		status = "okay";
		#address-cells = <0x01>;
		#size-cells = <0x00>;

		ports {
			#address-cells = <0x01>;
			#size-cells = <0x00>;

			port@0 {
				reg = <0x00>;
				#address-cells = <0x01>;
				#size-cells = <0x00>;

				endpoint@0 {
					reg = <0x00>;
					remote-endpoint = <0x60>;
					phandle = <0x59>;
				};

				endpoint@1 {
					reg = <0x01>;
					remote-endpoint = <0x61>;
					phandle = <0x5e>;
				};
			};

			port@1 {
				reg = <0x01>;

				endpoint {
					remote-endpoint = <0x62>;
					phandle = <0x65>;
				};
			};
		};

		panel@0 {
			compatible = "archos,oxygen101-panel";
			reg = <0x00>;
			backlight = <0x63>;
			power-supply = <0x64>;

			port {

				endpoint {
					remote-endpoint = <0x65>;
					phandle = <0x62>;
				};
			};
		};
	};

	lvds@ff96c000 {
		compatible = "rockchip,rk3288-lvds";
		reg = <0x00 0xff96c000 0x00 0x4000>;
		clocks = <0x07 0x167>;
		clock-names = "pclk_lvds";
		pinctrl-names = "lcdc";
		pinctrl-0 = <0x66>;
		power-domains = <0x55 0x09>;
		rockchip,grf = <0x38>;
		status = "disabled";

		ports {
			#address-cells = <0x01>;
			#size-cells = <0x00>;

			port@0 {
				reg = <0x00>;
				#address-cells = <0x01>;
				#size-cells = <0x00>;

				endpoint@0 {
					reg = <0x00>;
					remote-endpoint = <0x67>;
					phandle = <0x5a>;
				};

				endpoint@1 {
					reg = <0x01>;
					remote-endpoint = <0x68>;
					phandle = <0x5f>;
				};
			};

			port@1 {
				reg = <0x01>;
			};
		};
	};

	dp@ff970000 {
		compatible = "rockchip,rk3288-dp";
		reg = <0x00 0xff970000 0x00 0x4000>;
		interrupts = <0x00 0x62 0x04>;
		clocks = <0x07 0x69 0x07 0x163>;
		clock-names = "dp", "pclk";
		phys = <0x69>;
		phy-names = "dp";
		power-domains = <0x55 0x09>;
		resets = <0x07 0x6f>;
		reset-names = "dp";
		rockchip,grf = <0x38>;
		status = "disabled";

		ports {
			#address-cells = <0x01>;
			#size-cells = <0x00>;

			port@0 {
				reg = <0x00>;
				#address-cells = <0x01>;
				#size-cells = <0x00>;

				endpoint@0 {
					reg = <0x00>;
					remote-endpoint = <0x6a>;
					phandle = <0x58>;
				};

				endpoint@1 {
					reg = <0x01>;
					remote-endpoint = <0x6b>;
					phandle = <0x5d>;
				};
			};

			port@1 {
				reg = <0x01>;
			};
		};
	};

	hdmi@ff980000 {
		compatible = "rockchip,rk3288-dw-hdmi";
		reg = <0x00 0xff980000 0x00 0x20000>;
		reg-io-width = <0x04>;
		interrupts = <0x00 0x67 0x04>;
		clocks = <0x07 0x168 0x07 0x6d 0x07 0x6e>;
		clock-names = "iahb", "isfr", "cec";
		power-domains = <0x55 0x09>;
		rockchip,grf = <0x38>;
		#sound-dai-cells = <0x00>;
		status = "disabled";

		ports {
			#address-cells = <0x01>;
			#size-cells = <0x00>;

			port@0 {
				reg = <0x00>;
				#address-cells = <0x01>;
				#size-cells = <0x00>;

				endpoint@0 {
					reg = <0x00>;
					remote-endpoint = <0x6c>;
					phandle = <0x57>;
				};

				endpoint@1 {
					reg = <0x01>;
					remote-endpoint = <0x6d>;
					phandle = <0x5c>;
				};
			};

			port@1 {
				reg = <0x01>;
			};
		};
	};

	video-codec@ff9a0000 {
		compatible = "rockchip,rk3288-vpu";
		reg = <0x00 0xff9a0000 0x00 0x800>;
		interrupts = <0x00 0x09 0x04 0x00 0x0a 0x04>;
		interrupt-names = "vepu", "vdpu";
		clocks = <0x07 0xd0 0x07 0x1dc>;
		clock-names = "aclk", "hclk";
		iommus = <0x6e>;
		power-domains = <0x55 0x0c>;
	};

	iommu@ff9a0800 {
		compatible = "rockchip,iommu";
		reg = <0x00 0xff9a0800 0x00 0x100>;
		interrupts = <0x00 0x0b 0x04>;
		clocks = <0x07 0xd0 0x07 0x1dc>;
		clock-names = "aclk", "iface";
		#iommu-cells = <0x00>;
		power-domains = <0x55 0x0c>;
		phandle = <0x6e>;
	};

	iommu@ff9c0440 {
		compatible = "rockchip,iommu";
		reg = <0x00 0xff9c0440 0x00 0x40 0x00 0xff9c0480 0x00 0x40>;
		interrupts = <0x00 0x6f 0x04>;
		clocks = <0x07 0xcf 0x07 0x1db>;
		clock-names = "aclk", "iface";
		#iommu-cells = <0x00>;
		status = "disabled";
	};

	gpu@ffa30000 {
		compatible = "rockchip,rk3288-mali", "arm,mali-t760";
		reg = <0x00 0xffa30000 0x00 0x10000>;
		interrupts = <0x00 0x06 0x04 0x00 0x07 0x04 0x00 0x08 0x04>;
		interrupt-names = "job", "mmu", "gpu";
		clocks = <0x07 0xc0>;
		operating-points-v2 = <0x6f>;
		#cooling-cells = <0x02>;
		power-domains = <0x55 0x0d>;
		status = "disabled";
		phandle = <0x35>;
	};

	opp-table-1 {
		compatible = "operating-points-v2";
		phandle = <0x6f>;

		opp-100000000 {
			opp-hz = <0x00 0x5f5e100>;
			opp-microvolt = <0xe7ef0>;
		};

		opp-200000000 {
			opp-hz = <0x00 0xbebc200>;
			opp-microvolt = <0xe7ef0>;
		};

		opp-300000000 {
			opp-hz = <0x00 0x11e1a300>;
			opp-microvolt = <0xf4240>;
		};

		opp-400000000 {
			opp-hz = <0x00 0x17d78400>;
			opp-microvolt = <0x10c8e0>;
		};

		opp-600000000 {
			opp-hz = <0x00 0x23c34600>;
			opp-microvolt = <0x1312d0>;
		};
	};

	qos@ffaa0000 {
		compatible = "rockchip,rk3288-qos", "syscon";
		reg = <0x00 0xffaa0000 0x00 0x20>;
		phandle = <0x50>;
	};

	qos@ffaa0080 {
		compatible = "rockchip,rk3288-qos", "syscon";
		reg = <0x00 0xffaa0080 0x00 0x20>;
		phandle = <0x51>;
	};

	qos@ffad0000 {
		compatible = "rockchip,rk3288-qos", "syscon";
		reg = <0x00 0xffad0000 0x00 0x20>;
		phandle = <0x45>;
	};

	qos@ffad0100 {
		compatible = "rockchip,rk3288-qos", "syscon";
		reg = <0x00 0xffad0100 0x00 0x20>;
		phandle = <0x46>;
	};

	qos@ffad0180 {
		compatible = "rockchip,rk3288-qos", "syscon";
		reg = <0x00 0xffad0180 0x00 0x20>;
		phandle = <0x47>;
	};

	qos@ffad0400 {
		compatible = "rockchip,rk3288-qos", "syscon";
		reg = <0x00 0xffad0400 0x00 0x20>;
		phandle = <0x48>;
	};

	qos@ffad0480 {
		compatible = "rockchip,rk3288-qos", "syscon";
		reg = <0x00 0xffad0480 0x00 0x20>;
		phandle = <0x49>;
	};

	qos@ffad0500 {
		compatible = "rockchip,rk3288-qos", "syscon";
		reg = <0x00 0xffad0500 0x00 0x20>;
		phandle = <0x44>;
	};

	qos@ffad0800 {
		compatible = "rockchip,rk3288-qos", "syscon";
		reg = <0x00 0xffad0800 0x00 0x20>;
		phandle = <0x4a>;
	};

	qos@ffad0880 {
		compatible = "rockchip,rk3288-qos", "syscon";
		reg = <0x00 0xffad0880 0x00 0x20>;
		phandle = <0x4b>;
	};

	qos@ffad0900 {
		compatible = "rockchip,rk3288-qos", "syscon";
		reg = <0x00 0xffad0900 0x00 0x20>;
		phandle = <0x4c>;
	};

	qos@ffae0000 {
		compatible = "rockchip,rk3288-qos", "syscon";
		reg = <0x00 0xffae0000 0x00 0x20>;
		phandle = <0x4f>;
	};

	qos@ffaf0000 {
		compatible = "rockchip,rk3288-qos", "syscon";
		reg = <0x00 0xffaf0000 0x00 0x20>;
		phandle = <0x4d>;
	};

	qos@ffaf0080 {
		compatible = "rockchip,rk3288-qos", "syscon";
		reg = <0x00 0xffaf0080 0x00 0x20>;
		phandle = <0x4e>;
	};

	dma-controller@ffb20000 {
		compatible = "arm,pl330", "arm,primecell";
		reg = <0x00 0xffb20000 0x00 0x4000>;
		interrupts = <0x00 0x00 0x04 0x00 0x01 0x04>;
		#dma-cells = <0x01>;
		arm,pl330-broken-no-flushp;
		arm,pl330-periph-burst;
		clocks = <0x07 0xc1>;
		clock-names = "apb_pclk";
		phandle = <0x52>;
	};

	efuse@ffb40000 {
		compatible = "rockchip,rk3288-efuse";
		reg = <0x00 0xffb40000 0x00 0x20>;
		#address-cells = <0x01>;
		#size-cells = <0x01>;
		clocks = <0x07 0x171>;
		clock-names = "pclk_efuse";

		cpu-id@7 {
			reg = <0x07 0x10>;
		};

		cpu_leakage@17 {
			reg = <0x17 0x01>;
		};
	};

	interrupt-controller@ffc01000 {
		compatible = "arm,gic-400";
		interrupt-controller;
		#interrupt-cells = <0x03>;
		#address-cells = <0x00>;
		reg = <0x00 0xffc01000 0x00 0x1000 0x00 0xffc02000 0x00 0x2000 0x00 0xffc04000 0x00 0x2000 0x00 0xffc06000 0x00 0x2000>;
		interrupts = <0x01 0x09 0xf04>;
		phandle = <0x01>;
	};

	pinctrl {
		compatible = "rockchip,rk3288-pinctrl";
		rockchip,grf = <0x38>;
		rockchip,pmu = <0x06>;
		#address-cells = <0x02>;
		#size-cells = <0x02>;
		ranges;

		gpio@ff750000 {
			compatible = "rockchip,gpio-bank";
			reg = <0x00 0xff750000 0x00 0x100>;
			interrupts = <0x00 0x51 0x04>;
			clocks = <0x07 0x140>;
			gpio-controller;
			#gpio-cells = <0x02>;
			interrupt-controller;
			#interrupt-cells = <0x02>;
			phandle = <0x3e>;
		};

		gpio@ff780000 {
			compatible = "rockchip,gpio-bank";
			reg = <0x00 0xff780000 0x00 0x100>;
			interrupts = <0x00 0x52 0x04>;
			clocks = <0x07 0x141>;
			gpio-controller;
			#gpio-cells = <0x02>;
			interrupt-controller;
			#interrupt-cells = <0x02>;
		};

		gpio@ff790000 {
			compatible = "rockchip,gpio-bank";
			reg = <0x00 0xff790000 0x00 0x100>;
			interrupts = <0x00 0x53 0x04>;
			clocks = <0x07 0x142>;
			gpio-controller;
			#gpio-cells = <0x02>;
			interrupt-controller;
			#interrupt-cells = <0x02>;
		};

		gpio@ff7a0000 {
			compatible = "rockchip,gpio-bank";
			reg = <0x00 0xff7a0000 0x00 0x100>;
			interrupts = <0x00 0x54 0x04>;
			clocks = <0x07 0x143>;
			gpio-controller;
			#gpio-cells = <0x02>;
			interrupt-controller;
			#interrupt-cells = <0x02>;
		};

		gpio@ff7b0000 {
			compatible = "rockchip,gpio-bank";
			reg = <0x00 0xff7b0000 0x00 0x100>;
			interrupts = <0x00 0x55 0x04>;
			clocks = <0x07 0x144>;
			gpio-controller;
			#gpio-cells = <0x02>;
			interrupt-controller;
			#interrupt-cells = <0x02>;
			phandle = <0x15>;
		};

		gpio@ff7c0000 {
			compatible = "rockchip,gpio-bank";
			reg = <0x00 0xff7c0000 0x00 0x100>;
			interrupts = <0x00 0x56 0x04>;
			clocks = <0x07 0x145>;
			gpio-controller;
			#gpio-cells = <0x02>;
			interrupt-controller;
			#interrupt-cells = <0x02>;
		};

		gpio@ff7d0000 {
			compatible = "rockchip,gpio-bank";
			reg = <0x00 0xff7d0000 0x00 0x100>;
			interrupts = <0x00 0x57 0x04>;
			clocks = <0x07 0x146>;
			gpio-controller;
			#gpio-cells = <0x02>;
			interrupt-controller;
			#interrupt-cells = <0x02>;
		};

		gpio@ff7e0000 {
			compatible = "rockchip,gpio-bank";
			reg = <0x00 0xff7e0000 0x00 0x100>;
			interrupts = <0x00 0x58 0x04>;
			clocks = <0x07 0x147>;
			gpio-controller;
			#gpio-cells = <0x02>;
			interrupt-controller;
			#interrupt-cells = <0x02>;
			phandle = <0x75>;
		};

		gpio@ff7f0000 {
			compatible = "rockchip,gpio-bank";
			reg = <0x00 0xff7f0000 0x00 0x100>;
			interrupts = <0x00 0x59 0x04>;
			clocks = <0x07 0x148>;
			gpio-controller;
			#gpio-cells = <0x02>;
			interrupt-controller;
			#interrupt-cells = <0x02>;
		};

		hdmi {

			hdmi-cec-c0 {
				rockchip,pins = <0x07 0x10 0x02 0x70>;
			};

			hdmi-cec-c7 {
				rockchip,pins = <0x07 0x17 0x04 0x70>;
			};

			hdmi-ddc {
				rockchip,pins = <0x07 0x13 0x02 0x70 0x07 0x14 0x02 0x70>;
			};

			hdmi-ddc-unwedge {
				rockchip,pins = <0x07 0x13 0x00 0x71 0x07 0x14 0x02 0x70>;
			};
		};

		pcfg-output-low {
			output-low;
			phandle = <0x71>;
		};

		pcfg-pull-up {
			bias-pull-up;
			phandle = <0x72>;
		};

		pcfg-pull-down {
			bias-pull-down;
			phandle = <0x73>;
		};

		pcfg-pull-none {
			bias-disable;
			phandle = <0x70>;
		};

		pcfg-pull-none-12ma {
			bias-disable;
			drive-strength = <0x0c>;
			phandle = <0x74>;
		};

		suspend {

			global-pwroff {
				rockchip,pins = <0x00 0x00 0x01 0x70>;
			};

			ddrio-pwroff {
				rockchip,pins = <0x00 0x01 0x01 0x70>;
			};

			ddr0-retention {
				rockchip,pins = <0x00 0x02 0x01 0x72>;
			};

			ddr1-retention {
				rockchip,pins = <0x00 0x03 0x01 0x72>;
			};
		};

		edp {

			edp-hpd {
				rockchip,pins = <0x07 0x0b 0x02 0x73>;
			};
		};

		i2c0 {

			i2c0-xfer {
				rockchip,pins = <0x00 0x0f 0x01 0x70 0x00 0x10 0x01 0x70>;
				phandle = <0x3d>;
			};
		};

		i2c1 {

			i2c1-xfer {
				rockchip,pins = <0x08 0x04 0x01 0x70 0x08 0x05 0x01 0x70>;
				phandle = <0x28>;
			};
		};

		i2c2 {

			i2c2-xfer {
				rockchip,pins = <0x06 0x09 0x01 0x70 0x06 0x0a 0x01 0x70>;
				phandle = <0x3f>;
			};
		};

		i2c3 {

			i2c3-xfer {
				rockchip,pins = <0x02 0x10 0x01 0x70 0x02 0x11 0x01 0x70>;
				phandle = <0x29>;
			};
		};

		i2c4 {

			i2c4-xfer {
				rockchip,pins = <0x07 0x11 0x01 0x70 0x07 0x12 0x01 0x70>;
				phandle = <0x2a>;
			};
		};

		i2c5 {

			i2c5-xfer {
				rockchip,pins = <0x07 0x13 0x01 0x70 0x07 0x14 0x01 0x70>;
				phandle = <0x2b>;
			};
		};

		i2s0 {

			i2s0-bus {
				rockchip,pins = <0x06 0x00 0x01 0x70 0x06 0x01 0x01 0x70 0x06 0x02 0x01 0x70 0x06 0x03 0x01 0x70 0x06 0x04 0x01 0x70 0x06 0x08 0x01 0x70>;
				phandle = <0x54>;
			};
		};

		lcdc {

			lcdc-ctl {
				rockchip,pins = <0x01 0x18 0x01 0x70 0x01 0x19 0x01 0x70 0x01 0x1a 0x01 0x70 0x01 0x1b 0x01 0x70>;
				phandle = <0x66>;
			};
		};

		sdmmc {

			sdmmc-clk {
				rockchip,pins = <0x06 0x14 0x01 0x70>;
				phandle = <0x0b>;
			};

			sdmmc-cmd {
				rockchip,pins = <0x06 0x15 0x01 0x72>;
				phandle = <0x0c>;
			};

			sdmmc-cd {
				rockchip,pins = <0x06 0x16 0x01 0x72>;
			};

			sdmmc-bus1 {
				rockchip,pins = <0x06 0x10 0x01 0x72>;
			};

			sdmmc-bus4 {
				rockchip,pins = <0x06 0x10 0x01 0x72 0x06 0x11 0x01 0x72 0x06 0x12 0x01 0x72 0x06 0x13 0x01 0x72>;
				phandle = <0x0d>;
			};
		};

		sdio0 {

			sdio0-bus1 {
				rockchip,pins = <0x04 0x14 0x01 0x72>;
			};

			sdio0-bus4 {
				rockchip,pins = <0x04 0x14 0x01 0x72 0x04 0x15 0x01 0x72 0x04 0x16 0x01 0x72 0x04 0x17 0x01 0x72>;
				phandle = <0x10>;
			};

			sdio0-cmd {
				rockchip,pins = <0x04 0x18 0x01 0x72>;
				phandle = <0x11>;
			};

			sdio0-clk {
				rockchip,pins = <0x04 0x19 0x01 0x70>;
				phandle = <0x12>;
			};

			sdio0-cd {
				rockchip,pins = <0x04 0x1a 0x01 0x72>;
			};

			sdio0-wp {
				rockchip,pins = <0x04 0x1b 0x01 0x72>;
			};

			sdio0-pwr {
				rockchip,pins = <0x04 0x1c 0x01 0x72>;
			};

			sdio0-bkpwr {
				rockchip,pins = <0x04 0x1d 0x01 0x72>;
			};

			sdio0-int {
				rockchip,pins = <0x04 0x1e 0x01 0x72>;
			};
		};

		sdio1 {

			sdio1-bus1 {
				rockchip,pins = <0x03 0x18 0x04 0x72>;
			};

			sdio1-bus4 {
				rockchip,pins = <0x03 0x18 0x04 0x72 0x03 0x19 0x04 0x72 0x03 0x1a 0x04 0x72 0x03 0x1b 0x04 0x72>;
			};

			sdio1-cd {
				rockchip,pins = <0x03 0x1c 0x04 0x72>;
			};

			sdio1-wp {
				rockchip,pins = <0x03 0x1d 0x04 0x72>;
			};

			sdio1-bkpwr {
				rockchip,pins = <0x03 0x1e 0x04 0x72>;
			};

			sdio1-int {
				rockchip,pins = <0x03 0x1f 0x04 0x72>;
			};

			sdio1-cmd {
				rockchip,pins = <0x04 0x06 0x04 0x72>;
			};

			sdio1-clk {
				rockchip,pins = <0x04 0x07 0x04 0x70>;
			};

			sdio1-pwr {
				rockchip,pins = <0x04 0x09 0x04 0x72>;
			};
		};

		emmc {

			emmc-clk {
				rockchip,pins = <0x03 0x12 0x02 0x70>;
				phandle = <0x16>;
			};

			emmc-cmd {
				rockchip,pins = <0x03 0x10 0x02 0x72>;
				phandle = <0x17>;
			};

			emmc-pwr {
				rockchip,pins = <0x03 0x09 0x02 0x72>;
				phandle = <0x18>;
			};

			emmc-bus1 {
				rockchip,pins = <0x03 0x00 0x02 0x72>;
			};

			emmc-bus4 {
				rockchip,pins = <0x03 0x00 0x02 0x72 0x03 0x01 0x02 0x72 0x03 0x02 0x02 0x72 0x03 0x03 0x02 0x72>;
			};

			emmc-bus8 {
				rockchip,pins = <0x03 0x00 0x02 0x72 0x03 0x01 0x02 0x72 0x03 0x02 0x02 0x72 0x03 0x03 0x02 0x72 0x03 0x04 0x02 0x72 0x03 0x05 0x02 0x72 0x03 0x06 0x02 0x72 0x03 0x07 0x02 0x72>;
				phandle = <0x19>;
			};
		};

		spi0 {

			spi0-clk {
				rockchip,pins = <0x05 0x0c 0x01 0x72>;
				phandle = <0x1c>;
			};

			spi0-cs0 {
				rockchip,pins = <0x05 0x0d 0x01 0x72>;
				phandle = <0x1f>;
			};

			spi0-tx {
				rockchip,pins = <0x05 0x0e 0x01 0x72>;
				phandle = <0x1d>;
			};

			spi0-rx {
				rockchip,pins = <0x05 0x0f 0x01 0x72>;
				phandle = <0x1e>;
			};

			spi0-cs1 {
				rockchip,pins = <0x05 0x10 0x01 0x72>;
			};
		};

		spi1 {

			spi1-clk {
				rockchip,pins = <0x07 0x0c 0x02 0x72>;
				phandle = <0x20>;
			};

			spi1-cs0 {
				rockchip,pins = <0x07 0x0d 0x02 0x72>;
				phandle = <0x23>;
			};

			spi1-rx {
				rockchip,pins = <0x07 0x0e 0x02 0x72>;
				phandle = <0x22>;
			};

			spi1-tx {
				rockchip,pins = <0x07 0x0f 0x02 0x72>;
				phandle = <0x21>;
			};
		};

		spi2 {

			spi2-cs1 {
				rockchip,pins = <0x08 0x03 0x01 0x72>;
			};

			spi2-clk {
				rockchip,pins = <0x08 0x06 0x01 0x72>;
				phandle = <0x24>;
			};

			spi2-cs0 {
				rockchip,pins = <0x08 0x07 0x01 0x72>;
				phandle = <0x27>;
			};

			spi2-rx {
				rockchip,pins = <0x08 0x08 0x01 0x72>;
				phandle = <0x26>;
			};

			spi2-tx {
				rockchip,pins = <0x08 0x09 0x01 0x72>;
				phandle = <0x25>;
			};
		};

		uart0 {

			uart0-xfer {
				rockchip,pins = <0x04 0x10 0x01 0x72 0x04 0x11 0x01 0x70>;
				phandle = <0x2c>;
			};

			uart0-cts {
				rockchip,pins = <0x04 0x12 0x01 0x72>;
			};

			uart0-rts {
				rockchip,pins = <0x04 0x13 0x01 0x70>;
			};
		};

		uart1 {

			uart1-xfer {
				rockchip,pins = <0x05 0x08 0x01 0x72 0x05 0x09 0x01 0x70>;
				phandle = <0x2d>;
			};

			uart1-cts {
				rockchip,pins = <0x05 0x0a 0x01 0x72>;
			};

			uart1-rts {
				rockchip,pins = <0x05 0x0b 0x01 0x70>;
			};
		};

		uart2 {

			uart2-xfer {
				rockchip,pins = <0x07 0x16 0x01 0x72 0x07 0x17 0x01 0x70>;
				phandle = <0x2e>;
			};
		};

		uart3 {

			uart3-xfer {
				rockchip,pins = <0x07 0x07 0x01 0x72 0x07 0x08 0x01 0x70>;
				phandle = <0x2f>;
			};

			uart3-cts {
				rockchip,pins = <0x07 0x09 0x01 0x72>;
			};

			uart3-rts {
				rockchip,pins = <0x07 0x0a 0x01 0x70>;
			};
		};

		uart4 {

			uart4-xfer {
				rockchip,pins = <0x05 0x0f 0x03 0x72 0x05 0x0e 0x03 0x70>;
				phandle = <0x30>;
			};

			uart4-cts {
				rockchip,pins = <0x05 0x0c 0x03 0x72>;
			};

			uart4-rts {
				rockchip,pins = <0x05 0x0d 0x03 0x70>;
			};
		};

		tsadc {

			otp-pin {
				rockchip,pins = <0x00 0x0a 0x00 0x70>;
				phandle = <0x36>;
			};

			otp-out {
				rockchip,pins = <0x00 0x0a 0x01 0x70>;
				phandle = <0x37>;
			};
		};

		pwm0 {

			pwm0-pin {
				rockchip,pins = <0x07 0x00 0x01 0x70>;
				phandle = <0x40>;
			};
		};

		pwm1 {

			pwm1-pin {
				rockchip,pins = <0x07 0x01 0x01 0x70>;
				phandle = <0x41>;
			};
		};

		pwm2 {

			pwm2-pin {
				rockchip,pins = <0x07 0x16 0x03 0x70>;
				phandle = <0x42>;
			};
		};

		pwm3 {

			pwm3-pin {
				rockchip,pins = <0x07 0x17 0x03 0x70>;
				phandle = <0x43>;
			};
		};

		gmac {

			rgmii-pins {
				rockchip,pins = <0x03 0x1e 0x03 0x70 0x03 0x1f 0x03 0x70 0x03 0x1a 0x03 0x70 0x03 0x1b 0x03 0x70 0x03 0x1c 0x03 0x74 0x03 0x1d 0x03 0x74 0x03 0x18 0x03 0x74 0x03 0x19 0x03 0x74 0x04 0x00 0x03 0x70 0x04 0x05 0x03 0x70 0x04 0x06 0x03 0x70 0x04 0x09 0x03 0x74 0x04 0x04 0x03 0x74 0x04 0x01 0x03 0x70 0x04 0x03 0x03 0x70>;
			};

			rmii-pins {
				rockchip,pins = <0x03 0x1e 0x03 0x70 0x03 0x1f 0x03 0x70 0x03 0x1c 0x03 0x70 0x03 0x1d 0x03 0x70 0x04 0x00 0x03 0x70 0x04 0x05 0x03 0x70 0x04 0x04 0x03 0x70 0x04 0x01 0x03 0x70 0x04 0x02 0x03 0x70 0x04 0x03 0x03 0x70>;
			};
		};

		spdif {

			spdif-tx {
				rockchip,pins = <0x06 0x0b 0x01 0x70>;
				phandle = <0x53>;
			};
		};
	};

	chosen {
		stdout-path = "serial2:115200n8";
	};

	memory@0 {
		device_type = "memory";
		reg = <0x00 0x00 0x00 0x80000000>;
	};

	regulator-vcc-sys {
		compatible = "regulator-fixed";
		regulator-name = "vcc_sys";
		regulator-min-microvolt = <0x39fbc0>;
		regulator-max-microvolt = <0x39fbc0>;
		regulator-always-on;
		regulator-boot-on;
		phandle = <0x76>;
	};

	regulator-vcc-5v {
		compatible = "regulator-fixed";
		regulator-name = "vcc_5v";
		regulator-min-microvolt = <0x4c4b40>;
		regulator-max-microvolt = <0x4c4b40>;
		gpio = <0x75 0x0c 0x00>;
		enable-active-high;
		regulator-always-on;
		regulator-boot-on;
		vin-supply = <0x76>;
		phandle = <0x77>;
	};

	regulator-vcc-host-5v {
		compatible = "regulator-fixed";
		regulator-name = "vcc_host_5v";
		regulator-min-microvolt = <0x4c4b40>;
		regulator-max-microvolt = <0x4c4b40>;
		gpio = <0x3e 0x0e 0x00>;
		enable-active-high;
		vin-supply = <0x77>;
		phandle = <0x3b>;
	};

	backlight {
		compatible = "pwm-backlight";
		pwms = <0x78 0x00 0x61a8 0x00>;
		enable-gpios = <0x75 0x02 0x00>;
		brightness-levels = <0x00 0xff>;
		num-interpolated-steps = <0xff>;
		default-brightness-level = <0xc8>;
		power-supply = <0x76>;
		phandle = <0x63>;
	};

	gpio-keys {
		compatible = "gpio-keys";

		lid-switch {
			label = "Hall sensor";
			gpios = <0x3e 0x06 0x01>;
			linux,input-type = <0x05>;
			linux,code = <0x00>;
			wakeup-source;
		};
	};

	sdio-pwrseq {
		compatible = "mmc-pwrseq-simple";
		reset-gpios = <0x15 0x1c 0x01>;
		post-power-on-delay-ms = <0x32>;
		phandle = <0x0f>;
	};
};
